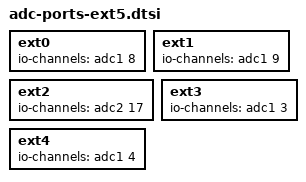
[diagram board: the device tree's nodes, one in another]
/*
 * Copyright (c) 2026
 * SPDX-License-Identifier: Apache-2.0
 *
 * Five fibril,fcan-adc-port children: ADC__0..ADC__4 (PC2, PC3, PA4, PA2,
 * PA3), in that order. Included inside the port node, at the position the
 * deployment wants them; the includer also includes
 * <fibril/robomaster_miniv4/adc.dtsi>.
 */

ext0 { io-channels = <&adc1 8>; };
ext1 { io-channels = <&adc1 9>; };
ext2 { io-channels = <&adc2 17>; };
ext3 { io-channels = <&adc1 3>; };
ext4 { io-channels = <&adc1 4>; };
